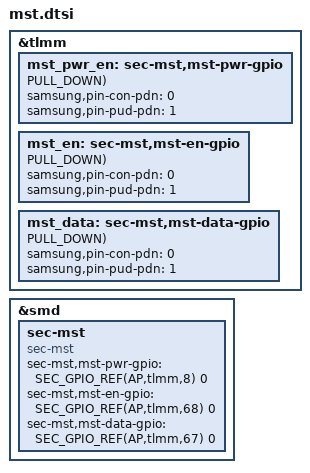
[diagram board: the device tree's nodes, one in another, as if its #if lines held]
/* Copyright (c) 2013, Samsung Electronics Corporation. All rights reserved.
 *
 * This program is free software; you can redistribute it and/or modify
 * it under the terms of the GNU General Public License version 2 and
 * only version 2 as published by the Free Software Foundation.
 *
 * This program is distributed in the hope that it will be useful,
 * but WITHOUT ANY WARRANTY; without even the implied warranty of
 * MERCHANTABILITY or FITNESS FOR A PARTICULAR PURPOSE.  See the
 * GNU General Public License for more details.
 */

&tlmm {
	mst_pwr_en: sec-mst,mst-pwr-gpio {
		GPIO_CONFIG_PUD(AP,tlmm,8, FUNC_OUTPUT, PULL_DOWN);
#if defined(CONFIG_ARCH_EXYNOS) || defined(CONFIG_ARCH_EXYNOS9)
		samsung,pin-con-pdn = <0>;
		samsung,pin-pud-pdn = <1>;
#endif
	};
};

&tlmm {
	mst_en: sec-mst,mst-en-gpio {
		GPIO_CONFIG_PUD(AP,tlmm,68, FUNC_OUTPUT, PULL_DOWN);
#if defined(CONFIG_ARCH_EXYNOS) || defined(CONFIG_ARCH_EXYNOS9)
		samsung,pin-con-pdn = <0>;
		samsung,pin-pud-pdn = <1>;
#endif
	};
};

&tlmm {
	mst_data: sec-mst,mst-data-gpio {
		GPIO_CONFIG_PUD(AP,tlmm,67, FUNC_OUTPUT, PULL_DOWN);
#if defined(CONFIG_ARCH_EXYNOS) || defined(CONFIG_ARCH_EXYNOS9)
		samsung,pin-con-pdn = <0>;
		samsung,pin-pud-pdn = <1>;
#endif
	};
};

&smd {
	sec-mst{
		compatible = "sec-mst";
		sec-mst,mst-pwr-gpio = <SEC_GPIO_REF(AP,tlmm,8) 0>;
		sec-mst,mst-en-gpio = <SEC_GPIO_REF(AP,tlmm,68) 0>;
		sec-mst,mst-data-gpio = <SEC_GPIO_REF(AP,tlmm,67) 0>;

		pinctrl-names = "default";
		pinctrl-0 = <&mst_pwr_en &mst_en &mst_data>;
	};
};


/* /home/dpi/qb5_8814/workspace/P4_1716/android/kernel/kmodule/mst/mst.a71xq.dtsi */

&smd {
	sec-mst {
		/delete-property/ pinctrl-names;
		/delete-property/ pinctrl-0;
	};
};
